# PIC32CK2051SG00144 register map
Vendor: Microchip Technology; Series: PIC32CKSG00; File version: 0
CPU: CM33 r0p0, little endian, MPU, FPU, DSP, 3 interrupt priority bits, 158 interrupts, 23 SAU regions
Registers are 32-bit, read-write, reset 0x0 unless marked. A register's access mark holds for its fields unless they carry their own. Offsets are from the block's base; [hi:lo] are bit positions; <NAME> marks a mode.

## FPU — Floating-point Extension
Base 0xE000EF30; register names take the prefix FPU_
Same registers: FPU_NS 0xE002EF30
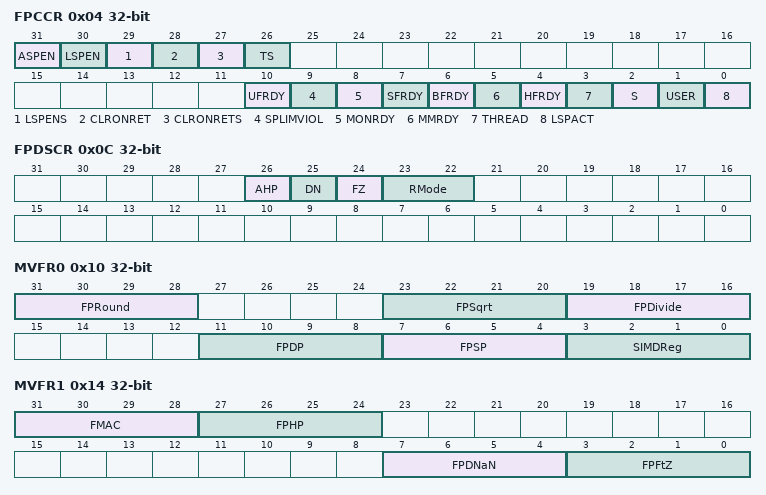
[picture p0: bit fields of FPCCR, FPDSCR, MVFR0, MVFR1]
0x04 FPCCR — Floating-Point Context Control Register
  [31] ASPEN — Automatic FP context save enable
  [30] LSPEN — Automatic lazy FP context save enable
  [29] LSPENS — LSPEN field writeable only from Secure state
  [28] CLRONRET — Clear FP caller saved registers enable
  [27] CLRONRETS — CLRONRET field writeable only from Secure state
  [26] TS — Treat FP registers as Secure enable
  [10] UFRDY — UsageFault exception set to pending
  [9] SPLIMVIOL — FP context violates the stack pointer limit
  [8] MONRDY — DebugMonitor exception set to pending
  [7] SFRDY — SecureFault exception set to pending
  [6] BFRDY — BusFault exception set to pending
  [5] MMRDY — MemManage exception set to pending
  [4] HFRDY — HardFault exception set to pending
  [3] THREAD — Thread mode when FP stack frame allocated
  [2] S — Security status of FP context
  [1] USER — Privilege level when FP stack frame allocated
  [0] LSPACT — Lazy preservation of FP state active
0x08 FPCAR — Floating-Point Context Address Register
  [31:3] ADDRESS — Address for FP registers push to exception stack
0x0C FPDSCR — Floating-Point Default Status Control Register
  [26] AHP — Alternative half-precision default value
  [25] DN — NaN default value
  [24] FZ — Flush-to-zero default value
  [23:22] RMode — Rounding mode default value
0x10 MVFR0 ro — Media and VFP Feature Register 0
  [31:28] FPRound — All FP rounding modes support
  [23:20] FPSqrt — FP square root operations support
  [19:16] FPDivide — FP divide operations support
  [11:8] FPDP — FP double-precision operations support
    2=YES (Supported)
  [7:4] FPSP — FP single-precision operations support
    2=YES (Supported)
  [3:0] SIMDReg — Size of FP register file
    1=16 x 64-bit registers
0x14 MVFR1 ro — Media and VFP Feature Register 1
  [31:28] FMAC — Fused multiply accumulate instructions
  [27:24] FPHP — Floating-point half-precision conversion instructions
    1=SP (Half-precision to single-precision supported); 2=BOTH (Half-precision to single- and double-precision supported)
  [7:4] FPDNaN — Propagation of NaN values support
  [3:0] FPFtZ — Floating-point subnormals flush-to-zero
0x18 MVFR2 ro — Media and VFP Feature Register 2
  [7:4] FPMisc — Floating-point miscellaneous features support
    4=YES (Selection, directed conversion to integer, VMINNM, and VMAXNM supported)

## FREQM — Frequency Meter
Base 0x44014000; register names take the prefix FREQM_
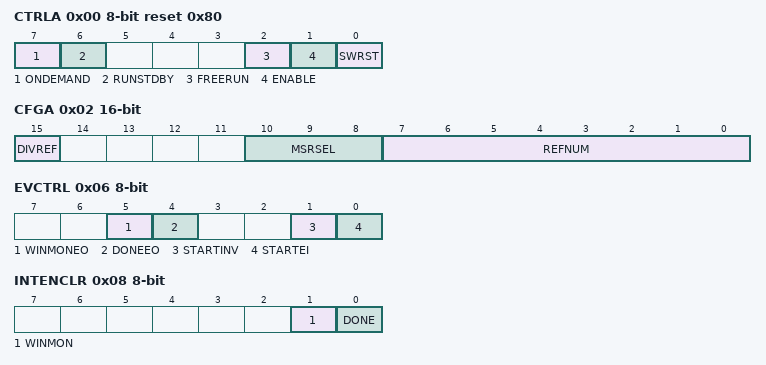
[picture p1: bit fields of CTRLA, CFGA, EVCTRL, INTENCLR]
0x00 CTRLA 8-bit reset 0x80 — Control A Register
  [7] ONDEMAND — On Demand Control
  [6] RUNSTDBY — Run In Standby
  [2] FREERUN — Free Running Mode
  [1] ENABLE
  [0] SWRST — Software Reset
0x01 CTRLB 8-bit wo — Control B Register
  [0] START — Start Measurement
0x02 CFGA 16-bit — Config A Register
  [15] DIVREF — Divide Reference Clock
    0=DIV1 (The reference clock is divided by 1); 1=DIV8 (The reference clock is divided by 8)
  [10:8] MSRSEL — Measurement Clock Selection
    0=GCLK (GCLK Input Clock); 1=CPU (CPU Input Clock)
  [7:0] REFNUM — Number of Reference Clock Cycles
0x04 CTRLC 8-bit — Control C Register
  [2:0] WINMODE — Window Monitor Mode
    0=DISABLE (No window mode (default)); 1=MODE1 (VALUE > WINLT); 2=MODE2 (VALUE < WINUT); 3=MODE3 (WINLT < VALUE < WINUT); 4=MODE4 (!(WINLT < VALUE < WINUT))
0x06 EVCTRL 8-bit — Event Control Register
  [5] WINMONEO — Window Monitor Event Out
  [4] DONEEO — Measurement Done Event Out
  [1] STARTINV — Start Measurement Event Invert Enable
  [0] STARTEI — Start Measurement Event Input Enable
0x08 INTENCLR 8-bit — Interrupt Enable Clear Register
  [1] WINMON — Window Monitor Interrupt Disable
  [0] DONE — Measurement Done Interrupt Disable
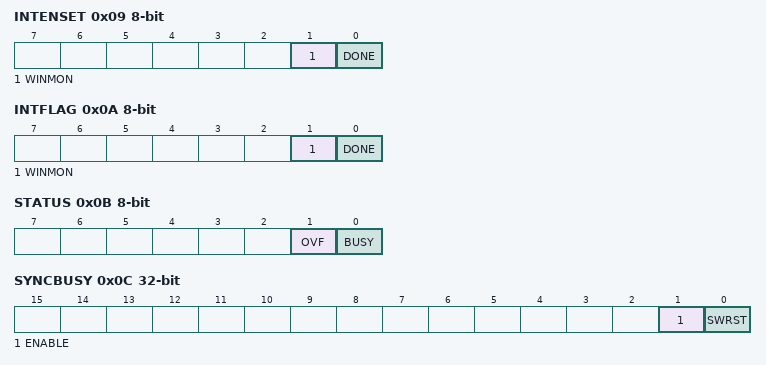
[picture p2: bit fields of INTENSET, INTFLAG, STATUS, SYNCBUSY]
0x09 INTENSET 8-bit — Interrupt Enable Set Register
  [1] WINMON — Window Monitor Interrupt Enable
  [0] DONE — Measurement Done Interrupt Enable
0x0A INTFLAG 8-bit — Interrupt Flag Register
  [1] WINMON — Window Monitor
  [0] DONE — Measurement Done
0x0B STATUS 8-bit
  [1] OVF — Sticky Count Value Overflow
  [0] BUSY — FREQM Status
0x0C SYNCBUSY ro — Synchronization Busy Register
  [1] ENABLE
  [0] SWRST — Software Reset
0x10 VALUE ro — Count Value Register
  [23:0] VALUE — Measurement Value
0x20 WINLT — Window Monitor Lower Threshold
  [23:0] WINLT — Window Lower Threshold
0x24 WINUT — Window Monitor Upper Threshold
  [23:0] WINUT — Window Upper Threshold

## Notices in the file
Copyright (c) 2022 Microchip Technology Inc.
SPDX-License-Identifier: Apache-2.0
Licensed under the Apache License, Version 2.0 (the "License");
you may not use this file except in compliance with the License.
You may obtain a copy of the License at
http://www.apache.org/licenses/LICENSE-2.0
Unless required by applicable law or agreed to in writing, software
distributed under the License is distributed on an "AS IS" BASIS,
WITHOUT WARRANTIES OR CONDITIONS OF ANY KIND, either express or implied.
See the License for the specific language governing permissions and
limitations under the License.
